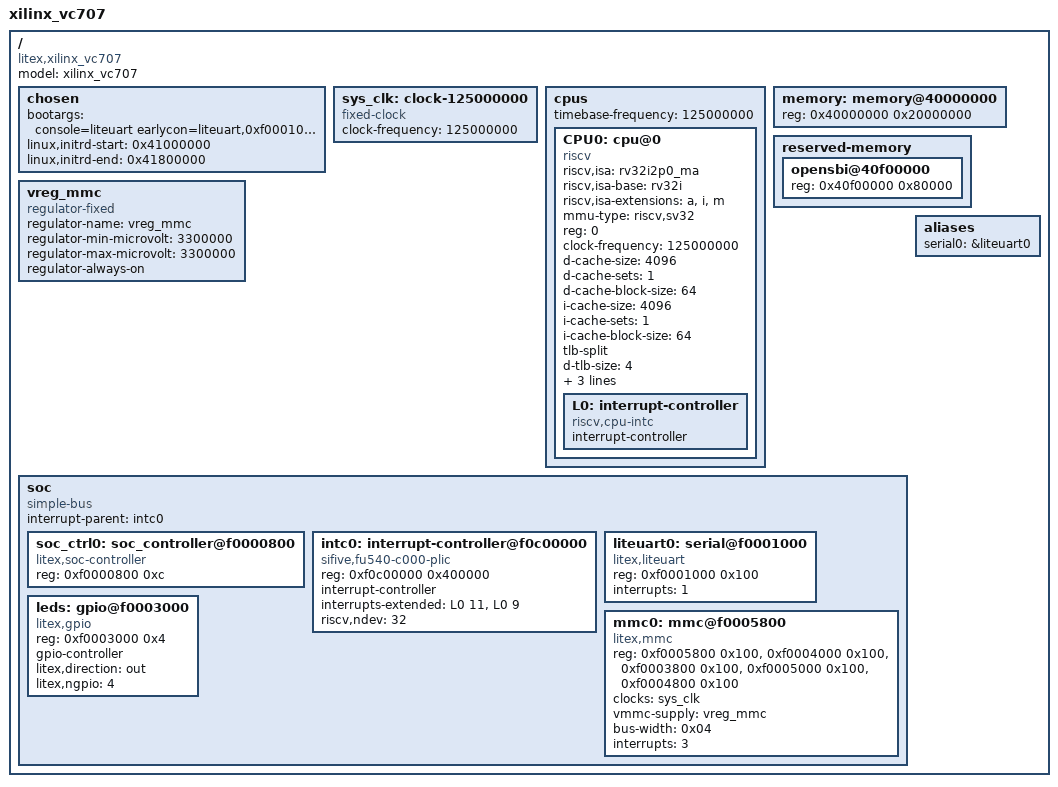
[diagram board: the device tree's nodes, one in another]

/dts-v1/;

/ {
        compatible = "litex,xilinx_vc707", "litex,soc";
        model = "xilinx_vc707";
        #address-cells = <1>;
        #size-cells    = <1>;


        chosen {
            bootargs = "console=liteuart earlycon=liteuart,0xf0001000 rootwait root=/dev/ram0";
            linux,initrd-start = <0x41000000>;
            linux,initrd-end   = <0x41800000>;
        };

        sys_clk: clock-125000000 {
            compatible = "fixed-clock";
            #clock-cells = <0>;
            clock-frequency  = <125000000>;
        };

        cpus {
            #address-cells = <1>;
            #size-cells    = <0>;
            timebase-frequency = <125000000>;

            CPU0: cpu@0 {
                device_type = "cpu";
                compatible = "riscv";
                riscv,isa = "rv32i2p0_ma";
                riscv,isa-base = "rv32i";
                riscv,isa-extensions = "a", "i", "m";
                mmu-type = "riscv,sv32";
                reg = <0>;
                clock-frequency = <125000000>;
                status = "okay";
                
                d-cache-size = <4096>;
                d-cache-sets = <1>;
                d-cache-block-size = <64>;

                i-cache-size = <4096>;
                i-cache-sets = <1>;
                i-cache-block-size = <64>;

                
                tlb-split;
                d-tlb-size = <4>;
                d-tlb-sets = <4>;

                i-tlb-size = <4>;
                i-tlb-sets = <4>;

                
                L0: interrupt-controller {
                    #address-cells = <0>;
                    #interrupt-cells = <0x00000001>;
                    interrupt-controller;
                    compatible = "riscv,cpu-intc";
                };
            };

            
        };

        memory: memory@40000000 {
            device_type = "memory";
            reg = <0x40000000 0x20000000>;
        };

        reserved-memory {
            #address-cells = <1>;
            #size-cells    = <1>;
            ranges;

            opensbi@40f00000 {
                reg = <0x40f00000 0x80000>;
            };

        };

        vreg_mmc: vreg_mmc {
            compatible = "regulator-fixed";
            regulator-name = "vreg_mmc";
            regulator-min-microvolt = <3300000>;
            regulator-max-microvolt = <3300000>;
            regulator-always-on;
        };

        soc {
            #address-cells = <1>;
            #size-cells    = <1>;
            compatible = "simple-bus";
            interrupt-parent = <&intc0>;
            ranges;

            soc_ctrl0: soc_controller@f0000800 {
                compatible = "litex,soc-controller";
                reg = <0xf0000800 0xc>;
                status = "okay";
            };

            intc0: interrupt-controller@f0c00000 {
                compatible = "sifive,fu540-c000-plic", "sifive,plic-1.0.0";
                reg = <0xf0c00000 0x400000>;
                #address-cells = <0>;
                #interrupt-cells = <1>;
                interrupt-controller;
                interrupts-extended = <
                    &L0 11 &L0 9>;
                riscv,ndev = <32>;
                
            };

            liteuart0: serial@f0001000 {
                compatible = "litex,liteuart";
                reg = <0xf0001000 0x100>;
                interrupts = <1>;
                status = "okay";
            };

            mmc0: mmc@f0005800 {
                compatible = "litex,mmc";
                reg = <0xf0005800 0x100>,
                      <0xf0004000 0x100>,
                      <0xf0003800 0x100>,
                      <0xf0005000 0x100>,
                      <0xf0004800 0x100>;
                reg-names = "phy", "core", "reader", "writer", "irq";
                clocks = <&sys_clk>;
                vmmc-supply = <&vreg_mmc>;
                bus-width = <0x04>;
                interrupts = <3>;
                status = "okay";
            };

            leds: gpio@f0003000 {
                compatible = "litex,gpio";
                reg = <0xf0003000 0x4>;
                gpio-controller;
                #gpio-cells = <2>;
                litex,direction = "out";
                status = "disabled";
            };

        };

        aliases {

                serial0 = &liteuart0;

        };

};

&leds {
        litex,ngpio = <4>;
        status = "okay";
};
